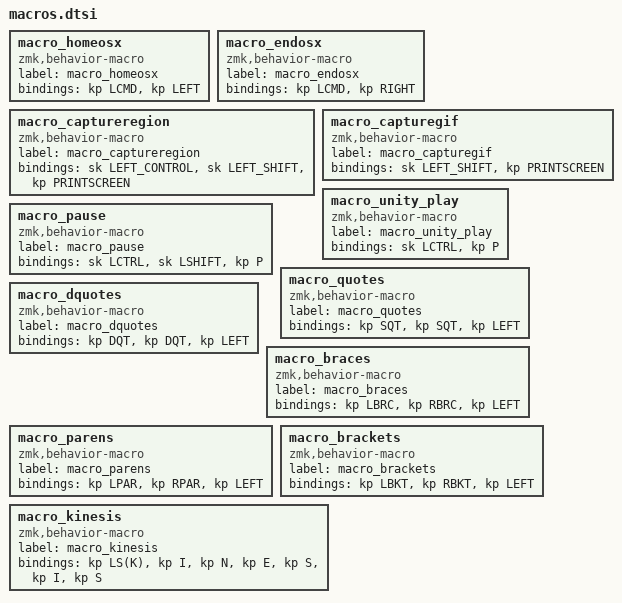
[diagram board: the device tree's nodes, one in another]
macro_homeosx: macro_homeosx{
compatible = "zmk,behavior-macro";
label = "macro_homeosx";
#binding-cells = <0>;
bindings = <&kp LCMD>, <&kp LEFT>;
};
macro_endosx: macro_endosx{
compatible = "zmk,behavior-macro";
label = "macro_endosx";
#binding-cells = <0>;
bindings = <&kp LCMD>, <&kp RIGHT>;
};
macro_captureregion: macro_captureregion{
compatible = "zmk,behavior-macro";
label = "macro_captureregion";
#binding-cells = <0>;
bindings = <&sk LEFT_CONTROL>, <&sk LEFT_SHIFT>, <&kp PRINTSCREEN>;
};
macro_capturegif: macro_capturegif{
compatible = "zmk,behavior-macro";
label = "macro_capturegif";
#binding-cells = <0>;
bindings = <&sk LEFT_SHIFT>, <&kp PRINTSCREEN>;
};
macro_unity_play: macro_unity_play{
compatible = "zmk,behavior-macro";
label = "macro_unity_play";
#binding-cells = <0>;
bindings = <&sk LCTRL>, <&kp P>;
};
macro_pause: macro_pause{
compatible = "zmk,behavior-macro";
label = "macro_pause";
#binding-cells = <0>;
bindings = <&sk LCTRL>, <&sk LSHIFT>, <&kp P>;
};
macro_quotes: macro_quotes{
compatible = "zmk,behavior-macro";
label = "macro_quotes";
#binding-cells = <0>;
bindings = <&kp SQT>, <&kp SQT>, <&kp LEFT>;
};
macro_dquotes: macro_dquotes{
compatible = "zmk,behavior-macro";
label = "macro_dquotes";
#binding-cells = <0>;
bindings = <&kp DQT>, <&kp DQT>, <&kp LEFT>;
};
macro_braces: macro_braces{
compatible = "zmk,behavior-macro";
label = "macro_braces";
#binding-cells = <0>;
bindings = <&kp LBRC>, <&kp RBRC>, <&kp LEFT>;
};
macro_parens: macro_parens{
compatible = "zmk,behavior-macro";
label = "macro_parens";
#binding-cells = <0>;
bindings = <&kp LPAR>, <&kp RPAR>, <&kp LEFT>;
};
macro_brackets: macro_brackets{
compatible = "zmk,behavior-macro";
label = "macro_brackets";
#binding-cells = <0>;
bindings = <&kp LBKT>, <&kp RBKT>, <&kp LEFT>;
};
macro_kinesis: macro_kinesis{
compatible = "zmk,behavior-macro";
label = "macro_kinesis";
#binding-cells = <0>;
bindings = <&kp LS(K)>, <&kp I>, <&kp N>, <&kp E>, <&kp S>, <&kp I>, <&kp S>;
};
